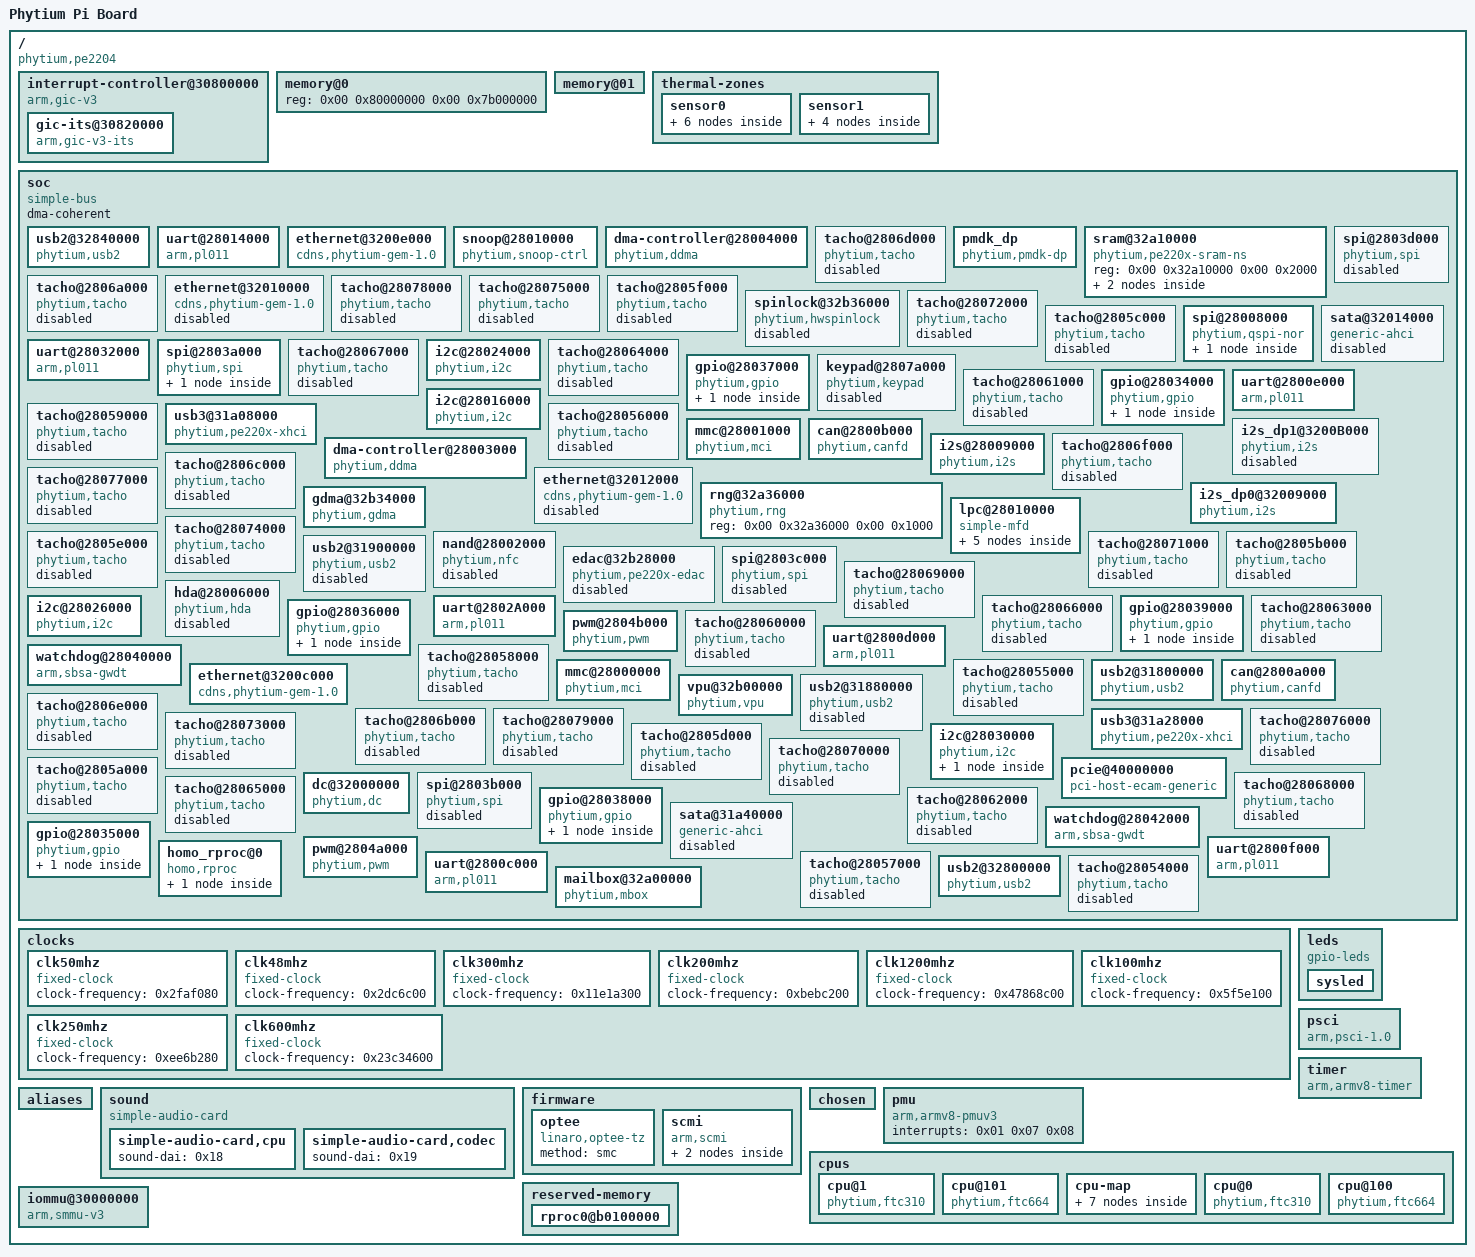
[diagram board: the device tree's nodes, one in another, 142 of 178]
/dts-v1/;

/ {
	#address-cells = <0x02>;
	model = "Phytium Pi Board";
	#size-cells = <0x02>;
	interrupt-parent = <0x01>;
	compatible = "phytium,pe2204";

	interrupt-controller@30800000 {
		#address-cells = <0x02>;
		interrupts = <0x01 0x09 0x08>;
		#size-cells = <0x02>;
		compatible = "arm,gic-v3";
		ranges;
		#interrupt-cells = <0x03>;
		reg = <0x00 0x30800000 0x00 0x20000 0x00 0x30880000 0x00 0x80000 0x00 0x30840000 0x00 0x10000 0x00 0x30850000 0x00 0x10000 0x00 0x30860000 0x00 0x10000>;
		phandle = <0x01>;
		interrupt-controller;

		gic-its@30820000 {
			msi-controller;
			compatible = "arm,gic-v3-its";
			reg = <0x00 0x30820000 0x00 0x20000>;
			phandle = <0x10>;
		};
	};

	memory@0 {
		device_type = "memory";
		reg = <0x00 0x80000000 0x00 0x7b000000>;
	};

	memory@01 {
		device_type = "memory";
		reg = <0x20 0x00 0x00 0x80000000>;
		numa-node-id = <0x00>;
	};

	thermal-zones {

		sensor0 {
			polling-delay = <0x3e8>;
			polling-delay-passive = <0x64>;
			thermal-sensors = <0x04 0x00>;

			trips {

				cpu_crit {
					temperature = <0x186a0>;
					hysteresis = <0x7d0>;
					type = "critical";
				};

				trip-point@0 {
					temperature = <0x124f8>;
					hysteresis = <0x00>;
					type = "passive";
				};

				trip-point@1 {
					temperature = <0x15f90>;
					hysteresis = <0x00>;
					type = "passive";
					phandle = <0x05>;
				};
			};

			cooling-maps {

				map0 {
					trip = <0x05>;
					cooling-device = <0x06 0xffffffff 0xffffffff 0x07 0xffffffff 0xffffffff>;
				};
			};
		};

		sensor1 {
			polling-delay = <0x3e8>;
			polling-delay-passive = <0x64>;
			thermal-sensors = <0x04 0x01>;

			trips {

				cpu_crit {
					temperature = <0x186a0>;
					hysteresis = <0x7d0>;
					type = "critical";
				};

				trip-point@0 {
					temperature = <0x124f8>;
					hysteresis = <0x00>;
					type = "passive";
				};

				trip-point@1 {
					temperature = <0x15f90>;
					hysteresis = <0x00>;
					type = "passive";
				};
			};
		};
	};

	soc {
		#address-cells = <0x02>;
		dma-coherent;
		#size-cells = <0x02>;
		compatible = "simple-bus";
		ranges;

		usb2@32840000 {
			interrupts = <0x00 0x0f 0x04>;
			compatible = "phytium,usb2";
			status = "okay";
			reg = <0x00 0x32840000 0x00 0x40000 0x00 0x328c0000 0x00 0x40000>;
			dr_mode = "host";
		};

		uart@28014000 {
			clock-names = "uartclk\0apb_pclk";
			interrupts = <0x00 0x5c 0x04>;
			clocks = <0x0e 0x0e>;
			compatible = "arm,pl011\0arm,primecell";
			status = "okay";
			reg = <0x00 0x28014000 0x00 0x1000>;
		};

		ethernet@3200e000 {
			phy-mode = "sgmii";
			clock-names = "pclk\0hclk\0tx_clk\0tsu_clk";
			interrupts = <0x00 0x3b 0x04 0x00 0x3c 0x04 0x00 0x3d 0x04 0x00 0x3e 0x04>;
			clocks = <0x14 0x15 0x15 0x14>;
			compatible = "cdns,phytium-gem-1.0";
			status = "okay";
			reg = <0x00 0x3200e000 0x00 0x2000>;
			magic-packet;
			use-mii;
		};

		snoop@28010000 {
			interrupts = <0x00 0x58 0x04>;
			compatible = "phytium,snoop-ctrl";
			reg = <0x00 0x28010000 0x00 0x1000>;
			snoop-ports = <0x80>;
		};

		dma-controller@28004000 {
			interrupts = <0x00 0x4c 0x04>;
			compatible = "phytium,ddma";
			reg = <0x00 0x28004000 0x00 0x1000>;
			dma-channels = <0x08>;
			#dma-cells = <0x02>;
		};

		tacho@2806d000 {
			interrupts = <0x00 0xdb 0x04>;
			clocks = <0x0e>;
			compatible = "phytium,tacho";
			status = "disabled";
			reg = <0x00 0x2806d000 0x00 0x1000>;
		};

		pmdk_dp {
			dp-mask = [01];
			compatible = "phytium,pmdk-dp";
			status = "okay";
			num-dp = <0x01>;
		};

		sram@32a10000 {
			#address-cells = <0x01>;
			#size-cells = <0x01>;
			compatible = "phytium,pe220x-sram-ns\0mmio-sram";
			ranges = <0x00 0x00 0x32a10000 0x2000>;
			reg = <0x00 0x32a10000 0x00 0x2000>;

			scp-shmem@0 {
				compatible = "arm,scmi-shmem";
				reg = <0x1000 0x400>;
			};

			scp-shmem@1 {
				compatible = "arm,scmi-shmem";
				reg = <0x1400 0x400>;
				phandle = <0x03>;
			};
		};

		tacho@2806a000 {
			interrupts = <0x00 0xd8 0x04>;
			clocks = <0x0e>;
			compatible = "phytium,tacho";
			status = "disabled";
			reg = <0x00 0x2806a000 0x00 0x1000>;
		};

		ethernet@32010000 {
			clock-names = "pclk\0hclk\0tx_clk\0tsu_clk";
			interrupts = <0x00 0x40 0x04 0x00 0x41 0x04 0x00 0x42 0x04 0x00 0x43 0x04>;
			clocks = <0x14 0x15 0x15 0x14>;
			compatible = "cdns,phytium-gem-1.0";
			status = "disabled";
			reg = <0x00 0x32010000 0x00 0x2000>;
			magic-packet;
		};

		tacho@28078000 {
			interrupts = <0x00 0xe6 0x04>;
			clocks = <0x0e>;
			compatible = "phytium,tacho";
			status = "disabled";
			reg = <0x00 0x28078000 0x00 0x1000>;
		};

		tacho@28075000 {
			interrupts = <0x00 0xe3 0x04>;
			clocks = <0x0e>;
			compatible = "phytium,tacho";
			status = "disabled";
			reg = <0x00 0x28075000 0x00 0x1000>;
		};

		tacho@2805f000 {
			interrupts = <0x00 0xcd 0x04>;
			clocks = <0x0e>;
			compatible = "phytium,tacho";
			status = "disabled";
			reg = <0x00 0x2805f000 0x00 0x1000>;
		};

		spinlock@32b36000 {
			nr-locks = <0x20>;
			compatible = "phytium,hwspinlock";
			status = "disabled";
			reg = <0x00 0x32b36000 0x00 0x1000>;
			#hwlock-cells = <0x01>;
		};

		tacho@28072000 {
			interrupts = <0x00 0xe0 0x04>;
			clocks = <0x0e>;
			compatible = "phytium,tacho";
			status = "disabled";
			reg = <0x00 0x28072000 0x00 0x1000>;
		};

		tacho@2805c000 {
			interrupts = <0x00 0xca 0x04>;
			clocks = <0x0e>;
			compatible = "phytium,tacho";
			status = "disabled";
			reg = <0x00 0x2805c000 0x00 0x1000>;
		};

		spi@2803d000 {
			#address-cells = <0x01>;
			num-cs = <0x04>;
			interrupts = <0x00 0xa2 0x04>;
			clocks = <0x0e>;
			#size-cells = <0x00>;
			compatible = "phytium,spi";
			status = "disabled";
			reg = <0x00 0x2803d000 0x00 0x1000>;
		};

		spi@28008000 {
			#address-cells = <0x01>;
			reg-names = "qspi\0qspi_mm";
			clocks = <0x0c>;
			#size-cells = <0x00>;
			compatible = "phytium,qspi-nor";
			status = "okay";
			reg = <0x00 0x28008000 0x00 0x1000 0x00 0x00 0x00 0xfffffff>;

			flash@0 {
				spi-max-frequency = <0x1312d00>;
				spi-rx-bus-width = <0x01>;
				compatible = "jedec,spi-nor";
				status = "okay";
				reg = <0x00>;
			};
		};

		sata@32014000 {
			interrupts = <0x00 0x2b 0x04>;
			compatible = "generic-ahci";
			status = "disabled";
			reg = <0x00 0x32014000 0x00 0x1000>;
		};

		uart@28032000 {
			clock-names = "uartclk\0apb_pclk";
			interrupts = <0x00 0x6b 0x04>;
			clocks = <0x0e 0x0e>;
			compatible = "arm,pl011\0arm,primecell";
			status = "okay";
			reg = <0x00 0x28032000 0x00 0x1000>;
		};

		spi@2803a000 {
			#address-cells = <0x01>;
			num-cs = <0x04>;
			interrupts = <0x00 0x9f 0x04>;
			clocks = <0x0e>;
			#size-cells = <0x00>;
			compatible = "phytium,spi";
			global-cs = <0x01>;
			status = "okay";
			reg = <0x00 0x2803a000 0x00 0x1000>;

			spidev@0 {
				spi-max-frequency = <0x2faf080>;
				compatible = "spidev";
				status = "disabled";
				reg = <0x00>;
			};
		};

		tacho@28067000 {
			interrupts = <0x00 0xd5 0x04>;
			clocks = <0x0e>;
			compatible = "phytium,tacho";
			status = "disabled";
			reg = <0x00 0x28067000 0x00 0x1000>;
		};

		i2c@28024000 {
			#address-cells = <0x01>;
			interrupts = <0x00 0x64 0x04>;
			clocks = <0x0e>;
			#size-cells = <0x00>;
			compatible = "phytium,i2c";
			status = "okay";
			reg = <0x00 0x28024000 0x00 0x1000>;
		};

		tacho@28064000 {
			interrupts = <0x00 0xd2 0x04>;
			clocks = <0x0e>;
			compatible = "phytium,tacho";
			status = "disabled";
			reg = <0x00 0x28064000 0x00 0x1000>;
		};

		gpio@28037000 {
			#address-cells = <0x01>;
			gpio-controller;
			interrupts = <0x00 0x9c 0x04>;
			#size-cells = <0x00>;
			compatible = "phytium,gpio";
			status = "okay";
			reg = <0x00 0x28037000 0x00 0x1000>;
			#gpio-cells = <0x02>;

			porta {
				compatible = "phytium,gpio-port";
				reg = <0x00>;
				ngpios = <0x10>;
			};
		};

		keypad@2807a000 {
			interrupts = <0x00 0xbd 0x04>;
			clocks = <0x0e>;
			compatible = "phytium,keypad";
			status = "disabled";
			reg = <0x00 0x2807a000 0x00 0x1000>;
		};

		tacho@28061000 {
			interrupts = <0x00 0xcf 0x04>;
			clocks = <0x0e>;
			compatible = "phytium,tacho";
			status = "disabled";
			reg = <0x00 0x28061000 0x00 0x1000>;
		};

		gpio@28034000 {
			#address-cells = <0x01>;
			gpio-controller;
			interrupts = <0x00 0x6c 0x04 0x00 0x6d 0x04 0x00 0x6e 0x04 0x00 0x6f 0x04 0x00 0x70 0x04 0x00 0x71 0x04 0x00 0x72 0x04 0x00 0x73 0x04 0x00 0x74 0x04 0x00 0x75 0x04 0x00 0x76 0x04 0x00 0x77 0x04 0x00 0x78 0x04 0x00 0x79 0x04 0x00 0x7a 0x04 0x00 0x7b 0x04>;
			#size-cells = <0x00>;
			compatible = "phytium,gpio";
			status = "okay";
			reg = <0x00 0x28034000 0x00 0x1000>;
			#gpio-cells = <0x02>;

			porta {
				compatible = "phytium,gpio-port";
				reg = <0x00>;
				ngpios = <0x10>;
			};
		};

		uart@2800e000 {
			clock-names = "uartclk\0apb_pclk";
			interrupts = <0x00 0x55 0x04>;
			clocks = <0x0d 0x0d>;
			compatible = "arm,pl011\0arm,primecell";
			status = "okay";
			reg = <0x00 0x2800e000 0x00 0x1000>;
		};

		tacho@28059000 {
			interrupts = <0x00 0xc7 0x04>;
			clocks = <0x0e>;
			compatible = "phytium,tacho";
			status = "disabled";
			reg = <0x00 0x28059000 0x00 0x1000>;
		};

		i2c@28016000 {
			#address-cells = <0x01>;
			interrupts = <0x00 0x5d 0x04>;
			clocks = <0x0e>;
			#size-cells = <0x00>;
			compatible = "phytium,i2c";
			status = "okay";
			reg = <0x00 0x28016000 0x00 0x1000>;
		};

		usb3@31a08000 {
			interrupts = <0x00 0x10 0x04>;
			compatible = "phytium,pe220x-xhci";
			status = "okay";
			reg = <0x00 0x31a08000 0x00 0x18000>;
		};

		tacho@28056000 {
			interrupts = <0x00 0xc4 0x04>;
			clocks = <0x0e>;
			compatible = "phytium,tacho";
			status = "disabled";
			reg = <0x00 0x28056000 0x00 0x1000>;
		};

		mmc@28001000 {
			clock-names = "phytium_mci_clk";
			cap-sd-highspeed;
			no-mmc;
			bus-width = <0x04>;
			non-removable;
			cap-sdio-irq;
			interrupts = <0x00 0x49 0x04>;
			clocks = <0x0b>;
			no-sd;
			compatible = "phytium,mci";
			status = "okay";
			reg = <0x00 0x28001000 0x00 0x1000>;
			max-frequency = <0x2faf080>;
		};

		can@2800b000 {
			clock-names = "can_clk";
			interrupts = <0x00 0x52 0x04>;
			clocks = <0x13>;
			compatible = "phytium,canfd";
			status = "okay";
			tx-fifo-depth = <0x40>;
			rx-fifo-depth = <0x40>;
			reg = <0x00 0x2800b000 0x00 0x1000>;
		};

		i2s_dp1@3200B000 {
			dai-name = "phytium-i2s-dp1";
			clock-names = "i2s_clk";
			interrupts = <0x00 0x30 0x04>;
			clocks = <0x0f>;
			compatible = "phytium,i2s";
			status = "disabled";
			reg = <0x00 0x3200b000 0x00 0x1000 0x00 0x3200a000 0x00 0x1000>;
		};

		i2s@28009000 {
			dai-name = "phytium-i2s-lsd";
			clock-names = "i2s_clk";
			interrupts = <0x00 0x4d 0x04>;
			clocks = <0x0f>;
			#sound-dai-cells = <0x00>;
			compatible = "phytium,i2s";
			status = "okay";
			reg = <0x00 0x28009000 0x00 0x1000 0x00 0x28005000 0x00 0x1000>;
			phandle = <0x18>;
		};

		tacho@2806f000 {
			interrupts = <0x00 0xdd 0x04>;
			clocks = <0x0e>;
			compatible = "phytium,tacho";
			status = "disabled";
			reg = <0x00 0x2806f000 0x00 0x1000>;
		};

		dma-controller@28003000 {
			interrupts = <0x00 0x4b 0x04>;
			compatible = "phytium,ddma";
			reg = <0x00 0x28003000 0x00 0x1000>;
			dma-channels = <0x08>;
			#dma-cells = <0x02>;
		};

		tacho@2806c000 {
			interrupts = <0x00 0xda 0x04>;
			clocks = <0x0e>;
			compatible = "phytium,tacho";
			status = "disabled";
			reg = <0x00 0x2806c000 0x00 0x1000>;
		};

		ethernet@32012000 {
			clock-names = "pclk\0hclk\0tx_clk\0tsu_clk";
			interrupts = <0x00 0x44 0x04 0x00 0x45 0x04 0x00 0x46 0x04 0x00 0x47 0x04>;
			clocks = <0x14 0x15 0x15 0x14>;
			compatible = "cdns,phytium-gem-1.0";
			status = "disabled";
			reg = <0x00 0x32012000 0x00 0x2000>;
			magic-packet;
		};

		tacho@28077000 {
			interrupts = <0x00 0xe5 0x04>;
			clocks = <0x0e>;
			compatible = "phytium,tacho";
			status = "disabled";
			reg = <0x00 0x28077000 0x00 0x1000>;
		};

		rng@32a36000 {
			compatible = "phytium,rng";
			status = "okay";
			reg = <0x00 0x32a36000 0x00 0x1000>;
		};

		i2s_dp0@32009000 {
			dai-name = "phytium-i2s-dp0";
			clock-names = "i2s_clk";
			interrupts = <0x00 0x2f 0x04>;
			clocks = <0x0f>;
			compatible = "phytium,i2s";
			status = "okay";
			reg = <0x00 0x32009000 0x00 0x1000 0x00 0x32008000 0x00 0x1000>;
		};

		gdma@32b34000 {
			max-outstanding = <0x10>;
			interrupts = <0x00 0xea 0x04>;
			compatible = "phytium,gdma";
			reg = <0x00 0x32b34000 0x00 0x1000>;
			dma-channels = <0x10>;
			#dma-cells = <0x01>;
		};

		lpc@28010000 {
			reg-io-width = <0x04>;
			#address-cells = <0x01>;
			#size-cells = <0x01>;
			compatible = "simple-mfd\0syscon";
			ranges = <0x00 0x00 0x28010000 0x1000>;
			reg = <0x00 0x28010000 0x00 0x1000>;

			kcs@28 {
				interrupts = <0x00 0x58 0x04>;
				compatible = "phytium,kcs-bmc";
				status = "disabled";
				reg = <0x28 0x01 0x34 0x01 0x40 0x01>;
			};

			bt@48 {
				interrupts = <0x00 0x58 0x04>;
				compatible = "phytium,bt-bmc";
				status = "disabled";
				reg = <0x48 0x20>;
			};

			kcs@24 {
				interrupts = <0x00 0x58 0x04>;
				compatible = "phytium,kcs-bmc";
				status = "disabled";
				reg = <0x24 0x01 0x30 0x01 0x3c 0x01>;
			};

			kcs@8c {
				interrupts = <0x00 0x58 0x04>;
				compatible = "phytium,kcs-bmc";
				status = "disabled";
				reg = <0x8c 0x01 0x90 0x01 0x94 0x01>;
			};

			kcs@2c {
				interrupts = <0x00 0x58 0x04>;
				compatible = "phytium,kcs-bmc";
				status = "disabled";
				reg = <0x2c 0x01 0x38 0x01 0x44 0x01>;
			};
		};

		tacho@28074000 {
			interrupts = <0x00 0xe2 0x04>;
			clocks = <0x0e>;
			compatible = "phytium,tacho";
			status = "disabled";
			reg = <0x00 0x28074000 0x00 0x1000>;
		};

		tacho@2805e000 {
			interrupts = <0x00 0xcc 0x04>;
			clocks = <0x0e>;
			compatible = "phytium,tacho";
			status = "disabled";
			reg = <0x00 0x2805e000 0x00 0x1000>;
		};

		nand@28002000 {
			interrupts = <0x00 0x4a 0x04>;
			compatible = "phytium,nfc";
			status = "disabled";
			reg = <0x00 0x28002000 0x00 0x1000>;
		};

		tacho@28071000 {
			interrupts = <0x00 0xdf 0x04>;
			clocks = <0x0e>;
			compatible = "phytium,tacho";
			status = "disabled";
			reg = <0x00 0x28071000 0x00 0x1000>;
		};

		tacho@2805b000 {
			interrupts = <0x00 0xc9 0x04>;
			clocks = <0x0e>;
			compatible = "phytium,tacho";
			status = "disabled";
			reg = <0x00 0x2805b000 0x00 0x1000>;
		};

		edac@32b28000 {
			interrupts = <0x00 0x00 0x04 0x00 0x01 0x04>;
			compatible = "phytium,pe220x-edac";
			status = "disabled";
			reg = <0x00 0x32b28000 0x00 0x1000 0x00 0x31400000 0x00 0x1000 0x00 0x31401000 0x00 0x1000>;
		};

		usb2@31900000 {
			interrupts = <0x00 0x22 0x04>;
			compatible = "phytium,usb2";
			status = "disabled";
			reg = <0x00 0x31900000 0x00 0x80000 0x00 0x319b0000 0x00 0x10000>;
			dr_mode = "peripheral";
		};

		spi@2803c000 {
			#address-cells = <0x01>;
			num-cs = <0x04>;
			interrupts = <0x00 0xa1 0x04>;
			clocks = <0x0e>;
			#size-cells = <0x00>;
			compatible = "phytium,spi";
			status = "disabled";
			reg = <0x00 0x2803c000 0x00 0x1000>;
		};

		tacho@28069000 {
			interrupts = <0x00 0xd7 0x04>;
			clocks = <0x0e>;
			compatible = "phytium,tacho";
			status = "disabled";
			reg = <0x00 0x28069000 0x00 0x1000>;
		};

		hda@28006000 {
			interrupts = <0x00 0x4e 0x04>;
			compatible = "phytium,hda";
			status = "disabled";
			reg = <0x00 0x28006000 0x00 0x1000>;
		};

		i2c@28026000 {
			#address-cells = <0x01>;
			interrupts = <0x00 0x65 0x04>;
			clocks = <0x0e>;
			#size-cells = <0x00>;
			compatible = "phytium,i2c";
			status = "okay";
			reg = <0x00 0x28026000 0x00 0x1000>;
		};

		tacho@28066000 {
			interrupts = <0x00 0xd4 0x04>;
			clocks = <0x0e>;
			compatible = "phytium,tacho";
			status = "disabled";
			reg = <0x00 0x28066000 0x00 0x1000>;
		};

		gpio@28039000 {
			#address-cells = <0x01>;
			gpio-controller;
			interrupts = <0x00 0x9e 0x04>;
			#size-cells = <0x00>;
			compatible = "phytium,gpio";
			status = "okay";
			reg = <0x00 0x28039000 0x00 0x1000>;
			#gpio-cells = <0x02>;

			porta {
				compatible = "phytium,gpio-port";
				reg = <0x00>;
				ngpios = <0x10>;
			};
		};

		tacho@28063000 {
			interrupts = <0x00 0xd1 0x04>;
			clocks = <0x0e>;
			compatible = "phytium,tacho";
			status = "disabled";
			reg = <0x00 0x28063000 0x00 0x1000>;
		};

		uart@2802A000 {
			clock-names = "uartclk\0apb_pclk";
			interrupts = <0x00 0x67 0x04>;
			clocks = <0x0e 0x0e>;
			compatible = "arm,pl011\0arm,primecell";
			status = "okay";
			reg = <0x00 0x2802a000 0x00 0x1000>;
		};

		gpio@28036000 {
			#address-cells = <0x01>;
			gpio-controller;
			interrupts = <0x00 0x8c 0x04 0x00 0x8d 0x04 0x00 0x8e 0x04 0x00 0x8f 0x04 0x00 0x90 0x04 0x00 0x91 0x04 0x00 0x92 0x04 0x00 0x93 0x04 0x00 0x94 0x04 0x00 0x95 0x04 0x00 0x96 0x04 0x00 0x97 0x04 0x00 0x98 0x04 0x00 0x99 0x04 0x00 0x9a 0x04 0x00 0x9b 0x04>;
			#size-cells = <0x00>;
			compatible = "phytium,gpio";
			status = "okay";
			reg = <0x00 0x28036000 0x00 0x1000>;
			phandle = <0x17>;
			#gpio-cells = <0x02>;

			porta {
				compatible = "phytium,gpio-port";
				reg = <0x00>;
				ngpios = <0x10>;
			};
		};

		pwm@2804b000 {
			phytium,db = <0x00 0x00 0x64 0x3e8 0x3e8 0x00>;
			interrupts = <0x00 0xae 0x04>;
			clocks = <0x0e>;
			compatible = "phytium,pwm";
			status = "okay";
			reg = <0x00 0x2804b000 0x00 0x1000>;
		};

		tacho@28060000 {
			interrupts = <0x00 0xce 0x04>;
			clocks = <0x0e>;
			compatible = "phytium,tacho";
			status = "disabled";
			reg = <0x00 0x28060000 0x00 0x1000>;
		};

		watchdog@28040000 {
			interrupts = <0x00 0xa4 0x04>;
			timeout-sec = <0x1e>;
			compatible = "arm,sbsa-gwdt";
			status = "okay";
			reg = <0x00 0x28041000 0x00 0x1000 0x00 0x28040000 0x00 0x1000>;
		};

		uart@2800d000 {
			clock-names = "uartclk\0apb_pclk";
			interrupts = <0x00 0x54 0x04>;
			clocks = <0x0d 0x0d>;
			compatible = "arm,pl011\0arm,primecell";
			status = "okay";
			reg = <0x00 0x2800d000 0x00 0x1000>;
		};

		tacho@28058000 {
			interrupts = <0x00 0xc6 0x04>;
			clocks = <0x0e>;
			compatible = "phytium,tacho";
			status = "disabled";
			reg = <0x00 0x28058000 0x00 0x1000>;
		};

		tacho@28055000 {
			interrupts = <0x00 0xc3 0x04>;
			clocks = <0x0e>;
			compatible = "phytium,tacho";
			status = "disabled";
			reg = <0x00 0x28055000 0x00 0x1000>;
		};

		mmc@28000000 {
			clock-names = "phytium_mci_clk";
			cap-sd-highspeed;
			no-mmc;
			bus-width = <0x04>;
			cap-sdio-irq;
			interrupts = <0x00 0x48 0x04>;
			clocks = <0x0b>;
			compatible = "phytium,mci";
			status = "okay";
			reg = <0x00 0x28000000 0x00 0x1000>;
			max-frequency = <0x2faf080>;
		};

		usb2@31800000 {
			interrupts = <0x00 0x20 0x04>;
			compatible = "phytium,usb2";
			status = "okay";
			reg = <0x00 0x31800000 0x00 0x80000 0x00 0x31990000 0x00 0x10000>;
			dr_mode = "host";
		};

		can@2800a000 {
			clock-names = "can_clk";
			interrupts = <0x00 0x51 0x04>;
			clocks = <0x13>;
			compatible = "phytium,canfd";
			status = "okay";
			tx-fifo-depth = <0x40>;
			rx-fifo-depth = <0x40>;
			reg = <0x00 0x2800a000 0x00 0x1000>;
		};

		ethernet@3200c000 {
			phy-mode = "sgmii";
			support-tsn;
			clock-names = "pclk\0hclk\0tx_clk\0tsu_clk";
			interrupts = <0x00 0x37 0x04 0x00 0x38 0x04 0x00 0x39 0x04 0x00 0x3a 0x04 0x00 0x1c 0x04 0x00 0x1d 0x04 0x00 0x1e 0x04 0x00 0x1f 0x04>;
			clocks = <0x14 0x15 0x15 0x14>;
			compatible = "cdns,phytium-gem-1.0";
			status = "okay";
			reg = <0x00 0x3200c000 0x00 0x2000>;
			magic-packet;
			use-mii;
		};

		vpu@32b00000 {
			interrupts = <0x00 0x0c 0x04>;
			compatible = "phytium,vpu";
			status = "okay";
			reg = <0x00 0x32b00000 0x00 0x20000>;
		};

		usb2@31880000 {
			interrupts = <0x00 0x21 0x04>;
			compatible = "phytium,usb2";
			status = "disabled";
			reg = <0x00 0x31880000 0x00 0x80000 0x00 0x319a0000 0x00 0x10000>;
			dr_mode = "peripheral";
		};

		tacho@2806e000 {
			interrupts = <0x00 0xdc 0x04>;
			clocks = <0x0e>;
			compatible = "phytium,tacho";
			status = "disabled";
			reg = <0x00 0x2806e000 0x00 0x1000>;
		};

		tacho@2806b000 {
			interrupts = <0x00 0xd9 0x04>;
			clocks = <0x0e>;
			compatible = "phytium,tacho";
			status = "disabled";
			reg = <0x00 0x2806b000 0x00 0x1000>;
		};

		tacho@28079000 {
			interrupts = <0x00 0xe7 0x04>;
			clocks = <0x0e>;
			compatible = "phytium,tacho";
			status = "disabled";
			reg = <0x00 0x28079000 0x00 0x1000>;
		};

		usb3@31a28000 {
			interrupts = <0x00 0x11 0x04>;
			compatible = "phytium,pe220x-xhci";
			status = "okay";
			reg = <0x00 0x31a28000 0x00 0x18000>;
		};

		tacho@28076000 {
			interrupts = <0x00 0xe4 0x04>;
			clocks = <0x0e>;
			compatible = "phytium,tacho";
			status = "disabled";
			reg = <0x00 0x28076000 0x00 0x1000>;
		};

		tacho@28073000 {
			interrupts = <0x00 0xe1 0x04>;
			clocks = <0x0e>;
			compatible = "phytium,tacho";
			status = "disabled";
			reg = <0x00 0x28073000 0x00 0x1000>;
		};

		tacho@2805d000 {
			interrupts = <0x00 0xcb 0x04>;
			clocks = <0x0e>;
			compatible = "phytium,tacho";
			status = "disabled";
			reg = <0x00 0x2805d000 0x00 0x1000>;
		};

		i2c@28030000 {
			#address-cells = <0x01>;
			interrupts = <0x00 0x6a 0x04>;
			clocks = <0x0e>;
			#size-cells = <0x00>;
			compatible = "phytium,i2c";
			status = "okay";
			reg = <0x00 0x28030000 0x00 0x1000>;

			es8336@10 {
				#sound-dai-cells = <0x00>;
				compatible = "everest,es8336";
				reg = <0x10>;
				phandle = <0x19>;
			};
		};

		pcie@40000000 {
			#address-cells = <0x03>;
			bus-range = <0x00 0xff>;
			interrupt-map = <0x00 0x00 0x00 0x01 0x01 0x00 0x00 0x00 0x04 0x04 0x00 0x00 0x00 0x02 0x01 0x00 0x00 0x00 0x05 0x04 0x00 0x00 0x00 0x03 0x01 0x00 0x00 0x00 0x06 0x04 0x00 0x00 0x00 0x04 0x01 0x00 0x00 0x00 0x07 0x04>;
			#size-cells = <0x02>;
			device_type = "pci";
			interrupt-map-mask = <0x00 0x00 0x00 0x07>;
			compatible = "pci-host-ecam-generic";
			ranges = <0x1000000 0x00 0x00 0x00 0x50000000 0x00 0xf00000 0x2000000 0x00 0x58000000 0x00 0x58000000 0x00 0x28000000 0x3000000 0x10 0x00 0x10 0x00 0x10 0x00>;
			#interrupt-cells = <0x01>;
			status = "okay";
			reg = <0x00 0x40000000 0x00 0x10000000>;
			iommu-map = <0x00 0x11 0x00 0x10000>;
			msi-parent = <0x10>;
		};

		tacho@28070000 {
			interrupts = <0x00 0xde 0x04>;
			clocks = <0x0e>;
			compatible = "phytium,tacho";
			status = "disabled";
			reg = <0x00 0x28070000 0x00 0x1000>;
		};

		tacho@2805a000 {
			interrupts = <0x00 0xc8 0x04>;
			clocks = <0x0e>;
			compatible = "phytium,tacho";
			status = "disabled";
			reg = <0x00 0x2805a000 0x00 0x1000>;
		};

		dc@32000000 {
			edp_mask = [00];
			interrupts = <0x00 0x2c 0x04>;
			pipe_mask = [01];
			compatible = "phytium,dc";
			status = "okay";
			reg = <0x00 0x32000000 0x00 0x8000>;
		};

		spi@2803b000 {
			#address-cells = <0x01>;
			num-cs = <0x04>;
			interrupts = <0x00 0xa0 0x04>;
			clocks = <0x0e>;
			#size-cells = <0x00>;
			compatible = "phytium,spi";
			status = "disabled";
			reg = <0x00 0x2803b000 0x00 0x1000>;
		};

		tacho@28068000 {
			interrupts = <0x00 0xd6 0x04>;
			clocks = <0x0e>;
			compatible = "phytium,tacho";
			status = "disabled";
			reg = <0x00 0x28068000 0x00 0x1000>;
		};

		tacho@28065000 {
			interrupts = <0x00 0xd3 0x04>;
			clocks = <0x0e>;
			compatible = "phytium,tacho";
			status = "disabled";
			reg = <0x00 0x28065000 0x00 0x1000>;
		};

		gpio@28038000 {
			#address-cells = <0x01>;
			gpio-controller;
			interrupts = <0x00 0x9d 0x04>;
			#size-cells = <0x00>;
			compatible = "phytium,gpio";
			status = "okay";
			reg = <0x00 0x28038000 0x00 0x1000>;
			#gpio-cells = <0x02>;

			porta {
				compatible = "phytium,gpio-port";
				reg = <0x00>;
				ngpios = <0x10>;
			};
		};

		tacho@28062000 {
			interrupts = <0x00 0xd0 0x04>;
			clocks = <0x0e>;
			compatible = "phytium,tacho";
			status = "disabled";
			reg = <0x00 0x28062000 0x00 0x1000>;
		};

		sata@31a40000 {
			interrupts = <0x00 0x2a 0x04>;
			compatible = "generic-ahci";
			status = "disabled";
			reg = <0x00 0x31a40000 0x00 0x1000>;
		};

		watchdog@28042000 {
			interrupts = <0x00 0xa5 0x04>;
			timeout-sec = <0x1e>;
			compatible = "arm,sbsa-gwdt";
			status = "okay";
			reg = <0x00 0x28043000 0x00 0x1000 0x00 0x28042000 0x00 0x1000>;
		};

		gpio@28035000 {
			#address-cells = <0x01>;
			gpio-controller;
			interrupts = <0x00 0x7c 0x04 0x00 0x7d 0x04 0x00 0x7e 0x04 0x00 0x7f 0x04 0x00 0x80 0x04 0x00 0x81 0x04 0x00 0x82 0x04 0x00 0x83 0x04 0x00 0x84 0x04 0x00 0x85 0x04 0x00 0x86 0x04 0x00 0x87 0x04 0x00 0x88 0x04 0x00 0x89 0x04 0x00 0x8a 0x04 0x00 0x8b 0x04>;
			#size-cells = <0x00>;
			compatible = "phytium,gpio";
			status = "okay";
			reg = <0x00 0x28035000 0x00 0x1000>;
			phandle = <0x16>;
			#gpio-cells = <0x02>;

			porta {
				compatible = "phytium,gpio-port";
				reg = <0x00>;
				ngpios = <0x10>;
			};
		};

		pwm@2804a000 {
			phytium,db = <0x00 0x00 0x64 0x3e8 0x3e8 0x00>;
			interrupts = <0x00 0xad 0x04>;
			clocks = <0x0e>;
			compatible = "phytium,pwm";
			status = "okay";
			reg = <0x00 0x2804a000 0x00 0x1000>;
		};

		uart@2800f000 {
			clock-names = "uartclk\0apb_pclk";
			interrupts = <0x00 0x56 0x04>;
			clocks = <0x0d 0x0d>;
			compatible = "arm,pl011\0arm,primecell";
			status = "okay";
			reg = <0x00 0x2800f000 0x00 0x1000>;
		};

		homo_rproc@0 {
			compatible = "homo,rproc";
			status = "okay";

			homo_core0@b0100000 {
				remote-processor = <0x03>;
				firmware-name = "openamp_core0.elf";
				memory-region = <0x12>;
				compatible = "homo,rproc-core";
				inter-processor-interrupt = <0x09>;
			};
		};

		uart@2800c000 {
			clock-names = "uartclk\0apb_pclk";
			interrupts = <0x00 0x53 0x04>;
			clocks = <0x0d 0x0d>;
			compatible = "arm,pl011\0arm,primecell";
			status = "okay";
			reg = <0x00 0x2800c000 0x00 0x1000>;
		};

		tacho@28057000 {
			interrupts = <0x00 0xc5 0x04>;
			clocks = <0x0e>;
			compatible = "phytium,tacho";
			status = "disabled";
			reg = <0x00 0x28057000 0x00 0x1000>;
		};

		usb2@32800000 {
			interrupts = <0x00 0x0e 0x04>;
			compatible = "phytium,usb2";
			status = "okay";
			reg = <0x00 0x32800000 0x00 0x40000 0x00 0x32880000 0x00 0x40000>;
			dr_mode = "host";
		};

		tacho@28054000 {
			interrupts = <0x00 0xc2 0x04>;
			clocks = <0x0e>;
			compatible = "phytium,tacho";
			status = "disabled";
			reg = <0x00 0x28054000 0x00 0x1000>;
		};

		mailbox@32a00000 {
			interrupts = <0x00 0x16 0x04>;
			#mbox-cells = <0x01>;
			compatible = "phytium,mbox";
			reg = <0x00 0x32a00000 0x00 0x1000>;
			phandle = <0x02>;
		};
	};

	clocks {
		#address-cells = <0x02>;
		#size-cells = <0x02>;
		ranges;

		clk50mhz {
			#clock-cells = <0x00>;
			clock-frequency = <0x2faf080>;
			compatible = "fixed-clock";
			phandle = <0x0e>;
		};

		clk48mhz {
			#clock-cells = <0x00>;
			clock-frequency = <0x2dc6c00>;
			compatible = "fixed-clock";
			phandle = <0x15>;
		};

		clk300mhz {
			#clock-cells = <0x00>;
			clock-frequency = <0x11e1a300>;
			compatible = "fixed-clock";
			phandle = <0x0c>;
		};

		clk200mhz {
			#clock-cells = <0x00>;
			clock-frequency = <0xbebc200>;
			compatible = "fixed-clock";
			phandle = <0x13>;
		};

		clk1200mhz {
			#clock-cells = <0x00>;
			clock-frequency = <0x47868c00>;
			compatible = "fixed-clock";
			phandle = <0x0b>;
		};

		clk100mhz {
			#clock-cells = <0x00>;
			clock-frequency = <0x5f5e100>;
			compatible = "fixed-clock";
			phandle = <0x0d>;
		};

		clk250mhz {
			#clock-cells = <0x00>;
			clock-frequency = <0xee6b280>;
			compatible = "fixed-clock";
			phandle = <0x14>;
		};

		clk600mhz {
			#clock-cells = <0x00>;
			clock-frequency = <0x23c34600>;
			compatible = "fixed-clock";
			phandle = <0x0f>;
		};
	};

	leds {
		compatible = "gpio-leds";

		sysled {
			linux,default-trigger = "none";
			label = "sysled";
			gpios = <0x16 0x05 0x00>;
		};
	};

	psci {
		method = "smc";
		sys_reset = <0x84000009>;
		sys_poweroff = <0x84000008>;
		compatible = "arm,psci-1.0";
		cpu_on = <0xc4000003>;
		cpu_suspend = <0xc4000001>;
		cpu_off = <0x84000002>;
	};

	timer {
		interrupts = <0x01 0x0d 0x08 0x01 0x0e 0x08 0x01 0x0b 0x08 0x01 0x0a 0x08>;
		clock-frequency = <0x2faf080>;
		compatible = "arm,armv8-timer";
	};

	aliases {
		ethernet0 = "/soc/ethernet@3200c000";
		serial5 = "/soc/uart@2802A000";
		serial3 = "/soc/uart@2800f000";
		ethernet3 = "/soc/ethernet@32012000";
		serial1 = "/soc/uart@2800d000";
		ethernet1 = "/soc/ethernet@3200e000";
		serial6 = "/soc/uart@28032000";
		serial4 = "/soc/uart@28014000";
		serial2 = "/soc/uart@2800e000";
		ethernet2 = "/soc/ethernet@32010000";
		serial0 = "/soc/uart@2800c000";
	};

	sound {
		simple-audio-card,hp-det-gpio = <0x17 0x0b 0x01>;
		simple-audio-card,name = "phytium,pe220x-i2s-audio";
		simple-audio-card,format = "i2s";
		simple-audio-card,widgets = "Microphone\0mic-in\0Headphone\0Headphones";
		simple-audio-card,routing = "MIC2\0mic-in";
		compatible = "simple-audio-card";
		simple-audio-card,pin-switches = "mic-in";

		simple-audio-card,cpu {
			sound-dai = <0x18>;
		};

		simple-audio-card,codec {
			sound-dai = <0x19>;
		};
	};

	firmware {

		optee {
			method = "smc";
			compatible = "linaro,optee-tz";
		};

		scmi {
			shmem = <0x03>;
			#address-cells = <0x01>;
			#size-cells = <0x00>;
			compatible = "arm,scmi";
			mboxes = <0x02 0x00>;
			mbox-names = "tx";

			protocol@15 {
				#thermal-sensor-cells = <0x01>;
				reg = <0x15>;
				phandle = <0x04>;
			};

			protocol@13 {
				#clock-cells = <0x01>;
				reg = <0x13>;
				phandle = <0x0a>;
			};
		};
	};

	chosen {
		bootargs = "console=ttyAMA1,115200 earlycon=pl011,0x2800d000 root=/dev/mmcblk0p1 rootfstype=ext4 rootwait  rw cma=256m ;";
		stdout-path = "serial1:115200n8";
	};

	pmu {
		interrupts = <0x01 0x07 0x08>;
		compatible = "arm,armv8-pmuv3";
	};

	cpus {
		#address-cells = <0x02>;
		#size-cells = <0x00>;

		cpu@1 {
			capacity-dmips-mhz = <0xb22>;
			clocks = <0x0a 0x02>;
			device_type = "cpu";
			compatible = "phytium,ftc310\0arm,armv8";
			reg = <0x00 0x201>;
			enable-method = "psci";
			phandle = <0x08>;
		};

		cpu@101 {
			capacity-dmips-mhz = <0x161c>;
			clocks = <0x0a 0x01>;
			device_type = "cpu";
			compatible = "phytium,ftc664\0arm,armv8";
			reg = <0x00 0x100>;
			enable-method = "psci";
			phandle = <0x09>;
		};

		cpu-map {

			cluster2 {

				core0 {
					cpu = <0x09>;
				};
			};

			cluster0 {

				core1 {
					cpu = <0x08>;
				};

				core0 {
					cpu = <0x06>;
				};
			};

			cluster1 {

				core0 {
					cpu = <0x07>;
				};
			};
		};

		cpu@0 {
			capacity-dmips-mhz = <0xb22>;
			clocks = <0x0a 0x02>;
			device_type = "cpu";
			compatible = "phytium,ftc310\0arm,armv8";
			reg = <0x00 0x200>;
			enable-method = "psci";
			phandle = <0x06>;
			#cooling-cells = <0x02>;
		};

		cpu@100 {
			capacity-dmips-mhz = <0x161c>;
			clocks = <0x0a 0x00>;
			device_type = "cpu";
			compatible = "phytium,ftc664\0arm,armv8";
			reg = <0x00 0x00>;
			enable-method = "psci";
			phandle = <0x07>;
			#cooling-cells = <0x02>;
		};
	};

	reserved-memory {
		#address-cells = <0x02>;
		#size-cells = <0x02>;
		ranges;

		rproc0@b0100000 {
			reg = <0x00 0xb0100000 0x00 0x19900000>;
			phandle = <0x12>;
			no-map;
		};
	};

	iommu@30000000 {
		dma-coherent;
		interrupts = <0x00 0xf0 0x01 0x00 0xef 0x01 0x00 0xec 0x01 0x00 0xf2 0x01>;
		#iommu-cells = <0x01>;
		compatible = "arm,smmu-v3";
		interrupt-names = "eventq\0priq\0cmdq-sync\0gerror";
		reg = <0x00 0x30000000 0x00 0x800000>;
		phandle = <0x11>;
	};
};
